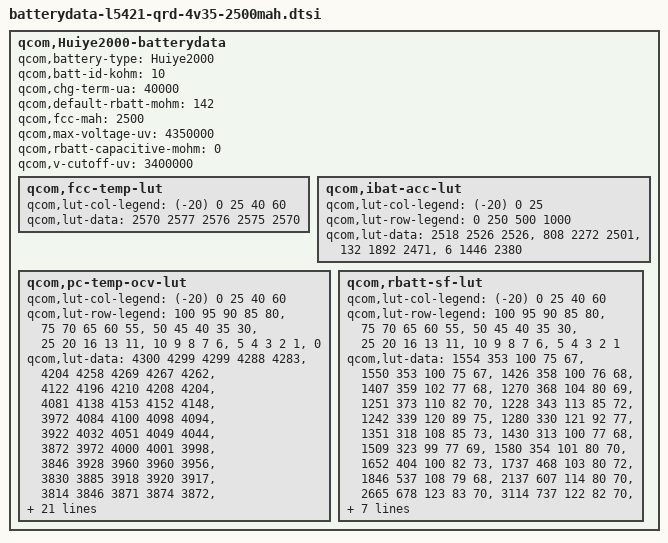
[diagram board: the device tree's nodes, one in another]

qcom,Huiye2000-batterydata {
	qcom,battery-type = "Huiye2000";
	qcom,batt-id-kohm = <10>;
	qcom,chg-term-ua = <40000>;
	qcom,default-rbatt-mohm = <142>;
	qcom,fcc-mah = <2500>;
	qcom,max-voltage-uv = <4350000>;
	qcom,rbatt-capacitive-mohm = <0>;
	qcom,v-cutoff-uv = <3400000>;

	qcom,fcc-temp-lut {
		qcom,lut-col-legend = <(-20) 0 25 40 60>;
		qcom,lut-data = <2570 2577 2576 2575 2570>;
	};

	qcom,ibat-acc-lut {
		qcom,lut-col-legend = <(-20) 0 25>;
		qcom,lut-row-legend = <0 250 500 1000>;
		qcom,lut-data = <2518 2526 2526>,
				<808 2272 2501>,
				<132 1892 2471>,
				<6 1446 2380>;
	};

	qcom,pc-temp-ocv-lut {
		qcom,lut-col-legend = <(-20) 0 25 40 60>;
		qcom,lut-row-legend = <100 95 90 85 80>,
					<75 70 65 60 55>,
					<50 45 40 35 30>,
					<25 20 16 13 11>,
					<10 9 8 7 6>,
					<5 4 3 2 1>,
					<0>;
		qcom,lut-data = <4300 4299 4299 4288 4283>,
				<4204 4258 4269 4267 4262>,
				<4122 4196 4210 4208 4204>,
				<4081 4138 4153 4152 4148>,
				<3972 4084 4100 4098 4094>,
				<3922 4032 4051 4049 4044>,
				<3872 3972 4000 4001 3998>,
				<3846 3928 3960 3960 3956>,
				<3830 3885 3918 3920 3917>,
				<3814 3846 3871 3874 3872>,
				<3799 3816 3837 3838 3836>,
				<3783 3796 3813 3814 3812>,
				<3766 3786 3794 3795 3794>,
				<3750 3776 3779 3780 3778>,
				<3734 3762 3768 3765 3759>,
				<3715 3746 3754 3748 3734>,
				<3693 3722 3734 3727 3714>,
				<3672 3701 3710 3704 3690>,
				<3652 3688 3684 3678 3668>,
				<3634 3680 3678 3673 3662>,
				<3623 3676 3676 3671 3661>,
				<3612 3671 3674 3669 3659>,
				<3596 3666 3670 3666 3656>,
				<3579 3659 3666 3663 3652>,
				<3557 3646 3658 3654 3641>,
				<3530 3624 3636 3630 3612>,
				<3497 3586 3592 3585 3566>,
				<3450 3529 3531 3524 3504>,
				<3382 3444 3446 3440 3420>,
				<3254 3308 3319 3314 3298>,
				<3000 3000 3000 3000 3026>;
	};

	qcom,rbatt-sf-lut {
		qcom,lut-col-legend = <(-20) 0 25 40 60>;
		qcom,lut-row-legend = <100 95 90 85 80>,
					<75 70 65 60 55>,
					<50 45 40 35 30>,
					<25 20 16 13 11>,
					<10 9 8 7 6>,
					<5 4 3 2 1>;
		qcom,lut-data = <1554 353 100 75 67>,
				<1550 353 100 75 67>,
				<1426 358 100 76 68>,
				<1407 359 102 77 68>,
				<1270 368 104 80 69>,
				<1251 373 110 82 70>,
				<1228 343 113 85 72>,
				<1242 339 120 89 75>,
				<1280 330 121 92 77>,
				<1351 318 108 85 73>,
				<1430 313 100 77 68>,
				<1509 323 99 77 69>,
				<1580 354 101 80 70>,
				<1652 404 100 82 73>,
				<1737 468 103 80 72>,
				<1846 537 108 79 68>,
				<2137 607 114 80 70>,
				<2665 678 123 83 70>,
				<3114 737 122 82 70>,
				<3617 800 125 84 70>,
				<4030 839 130 85 72>,
				<4554 891 135 87 73>,
				<5183 945 142 91 75>,
				<6000 1012 151 94 77>,
				<7111 1087 162 97 77>,
				<8641 1176 169 96 75>,
				<11045 1289 180 99 76>,
				<14780 1460 206 104 80>,
				<21542 1941 247 119 89>,
				<43008 3882 359 165 118>;
	};
};
/* TEST_DB_ID=TEST_ID_NOT_SET */
